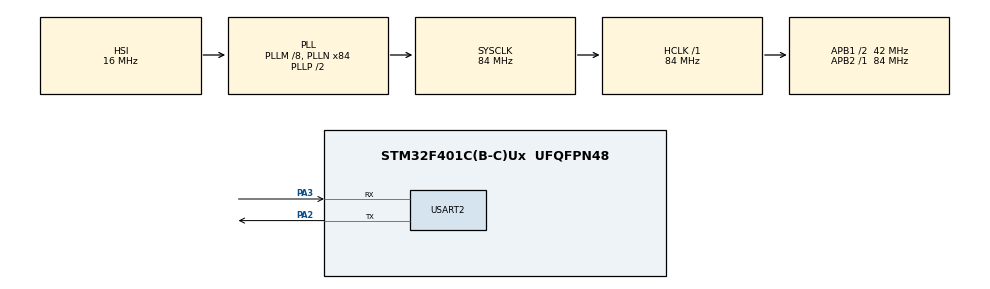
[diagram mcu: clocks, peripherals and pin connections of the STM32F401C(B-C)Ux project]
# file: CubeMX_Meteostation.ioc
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ADC1.Channel-0\#ChannelRegularConversion=ADC_CHANNEL_TEMPSENSOR
ADC1.ClockPrescaler=ADC_CLOCK_SYNC_PCLK_DIV4
ADC1.NbrOfConversionFlag=1
ADC1.Rank-0\#ChannelRegularConversion=1
ADC1.SamplingTime-0\#ChannelRegularConversion=ADC_SAMPLETIME_3CYCLES
ADC1.master=1
Mcu.Family=STM32F4
Mcu.Name=STM32F401C(B-C)Ux
Mcu.Package=UFQFPN48
NVIC.PriorityGroup=NVIC_PRIORITYGROUP_4
NVIC.USART2_IRQn=true\:0\:0\:false\:false\:true\:true\:true\:true
PA13.Mode=Serial_Wire
PA13.Signal=SYS_JTMS-SWDIO
PA14.Mode=Serial_Wire
PA14.Signal=SYS_JTCK-SWCLK
PA2.Mode=Asynchronous
PA2.Signal=USART2_TX
PA3.GPIO_PuPd=GPIO_PULLUP
PA3.Mode=Asynchronous
PA3.Signal=USART2_RX
ProjectManager.HeapSize=0x200
ProjectManager.StackSize=0x400
ProjectManager.TargetToolchain=CMake
RCC.48MHZClocksFreq_Value=42000000
RCC.AHBFreq_Value=84000000
RCC.APB1CLKDivider=RCC_HCLK_DIV2
RCC.APB1Freq_Value=42000000
RCC.APB1TimFreq_Value=84000000
RCC.APB2Freq_Value=84000000
RCC.APB2TimFreq_Value=84000000
RCC.CortexFreq_Value=84000000
RCC.HCLKFreq_Value=84000000
RCC.HSE_VALUE=25000000
RCC.HSI_VALUE=16000000
RCC.LSE_VALUE=32768
RCC.PLLM=8
RCC.PLLN=84
RCC.SYSCLKFreq_VALUE=84000000
RCC.SYSCLKSource=RCC_SYSCLKSOURCE_PLLCLK
RCC.VCOOutputFreq_Value=168000000
USART2.VirtualMode=VM_ASYNC
VP_ADC1_TempSens_Input.Mode=IN-TempSens
VP_RTC_VS_RTC_Activate.Mode=RTC_Enabled
board=custom

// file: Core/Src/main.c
/* USER CODE BEGIN Header */
/**
  ******************************************************************************
  * @file           : main.c
  * @brief          : Main program body
  ******************************************************************************
  * @attention
  *
  * Copyright (c) 2026 STMicroelectronics.
  * All rights reserved.
  *
  * This software is licensed under terms that can be found in the LICENSE file
  * in the root directory of this software component.
  * If no LICENSE file comes with this software, it is provided AS-IS.
  *
  ******************************************************************************
  */
/* USER CODE END Header */
#include "main.h"
#include "adc.h"
#include "rtc.h"
#include "stm32f401xc.h"
#include "usart.h"
#include "gpio.h"

/* USER CODE BEGIN Includes */
#include "app.h"
#include "driver_uart.h"
/* USER CODE END Includes */

/* USER CODE BEGIN PV */
const uint8_t * volatile g_assert_file;
volatile uint32_t g_assert_line;
/* USER CODE END PV */

void SystemClock_Config(void);

int main(void)
{

  /* MCU Configuration--------------------------------------------------------*/

  /* Reset of all peripherals, Initializes the Flash interface and the Systick. */
  HAL_Init();

  /* Configure the system clock */
  SystemClock_Config();

  /* Initialize all configured peripherals */
  MX_GPIO_Init();
  MX_ADC1_Init();
  MX_USART2_UART_Init();
  MX_RTC_Init();
  /* USER CODE BEGIN 2 */
  drv_uart_init(&huart2);
  app_init();
  /* USER CODE END 2 */

  /* Infinite loop */
  while (1)
  {

  }
}

void SystemClock_Config(void)
{
  RCC_OscInitTypeDef RCC_OscInitStruct = {0};
  RCC_ClkInitTypeDef RCC_ClkInitStruct = {0};

  /** Configure the main internal regulator output voltage
  */
  __HAL_RCC_PWR_CLK_ENABLE();
  __HAL_PWR_VOLTAGESCALING_CONFIG(PWR_REGULATOR_VOLTAGE_SCALE2);

  /** Initializes the RCC Oscillators according to the specified parameters
  * in the RCC_OscInitTypeDef structure.
  */
  RCC_OscInitStruct.OscillatorType = RCC_OSCILLATORTYPE_HSI|RCC_OSCILLATORTYPE_LSI;
  RCC_OscInitStruct.HSIState = RCC_HSI_ON;
  RCC_OscInitStruct.HSICalibrationValue = RCC_HSICALIBRATION_DEFAULT;
  RCC_OscInitStruct.LSIState = RCC_LSI_ON;
  RCC_OscInitStruct.PLL.PLLState = RCC_PLL_ON;
  RCC_OscInitStruct.PLL.PLLSource = RCC_PLLSOURCE_HSI;
  RCC_OscInitStruct.PLL.PLLM = 8;
  RCC_OscInitStruct.PLL.PLLN = 84;
  RCC_OscInitStruct.PLL.PLLP = RCC_PLLP_DIV2;
  RCC_OscInitStruct.PLL.PLLQ = 4;
  if (HAL_RCC_OscConfig(&RCC_OscInitStruct) != HAL_OK)
  {
    Error_Handler();
  }

  /** Initializes the CPU, AHB and APB buses clocks
  */
  RCC_ClkInitStruct.ClockType = RCC_CLOCKTYPE_HCLK|RCC_CLOCKTYPE_SYSCLK
                              |RCC_CLOCKTYPE_PCLK1|RCC_CLOCKTYPE_PCLK2;
  RCC_ClkInitStruct.SYSCLKSource = RCC_SYSCLKSOURCE_PLLCLK;
  RCC_ClkInitStruct.AHBCLKDivider = RCC_SYSCLK_DIV1;
  RCC_ClkInitStruct.APB1CLKDivider = RCC_HCLK_DIV2;
  RCC_ClkInitStruct.APB2CLKDivider = RCC_HCLK_DIV1;

  if (HAL_RCC_ClockConfig(&RCC_ClkInitStruct, FLASH_LATENCY_2) != HAL_OK)
  {
    Error_Handler();
  }
}

void Error_Handler(void)
{
  __disable_irq();
  while (1)
  {
  }
}
#ifdef USE_FULL_ASSERT
/**
  * @brief  Reports the name of the source file and the source line number
  *         where the assert_param error has occurred.
  * @param  file: pointer to the source file name
  * @param  line: assert_param error line source number
  * @retval None
  */
void assert_failed(uint8_t *file, uint32_t line)
{
  /* USER CODE BEGIN 6 */
  __disable_irq();
  g_assert_file = file;
  g_assert_line = line;

  if ((CoreDebug->DHCSR & CoreDebug_DHCSR_C_DEBUGEN_Msk) != 0U)
  {
    __BKPT(0);
  }

  /* Debug build/Preset: when an assert is triggered without a debugger attached,
  the device halts in while(1) (expected behavior).
  In release builds, USE_FULL_ASSERT is not defined, so this function is not called. */
  while (1)
  {
  }
  /* USER CODE END 6 */

}
#endif /* USE_FULL_ASSERT */
